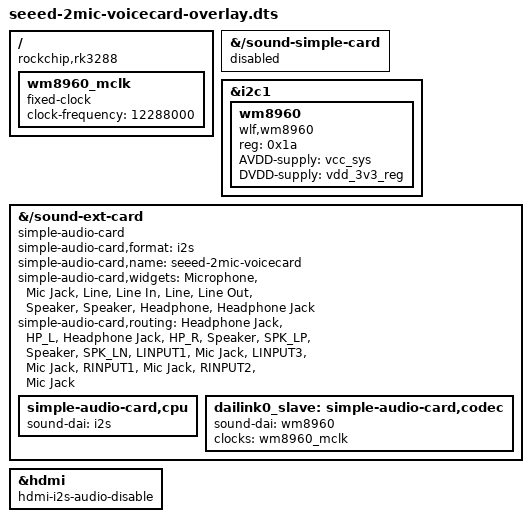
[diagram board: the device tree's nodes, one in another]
/dts-v1/;
/plugin/;

/ {
        compatible = "rockchip,rk3288";

        fragment@0 {
                target-path ="/sound-simple-card";
                __overlay__ {
                        status = "disabled";
                };
        };

        fragment@1 {
                target-path="/";
                __overlay__ {
                        wm8960_mclk: wm8960_mclk {
                                compatible = "fixed-clock";
                                #clock-cells = <0>;
                                clock-frequency = <12288000>;
                        };
                };
        };

        fragment@2 {
                target = <&i2c1>;
                __overlay__ {
                        #address-cells = <1>;
                        #size-cells = <0>;
                        status = "okay";

                        wm8960: wm8960 {
                                compatible = "wlf,wm8960";
                                reg = <0x1a>;
                                #sound-dai-cells = <0>;
                                AVDD-supply = <&vcc_sys>;
                                DVDD-supply = <&vdd_3v3_reg>;
                        };
                };
        };

        fragment@3 {
                target-path = "/sound-ext-card";
                slave_overlay: __overlay__ {
                        compatible = "simple-audio-card";
                        simple-audio-card,format = "i2s";
                        simple-audio-card,name = "seeed-2mic-voicecard";
                        status = "okay";
                        simple-audio-card,widgets =
                                "Microphone", "Mic Jack",
                                "Line", "Line In",
                                "Line", "Line Out",
                                "Speaker", "Speaker",
                                "Headphone", "Headphone Jack";
                        simple-audio-card,routing =
                                "Headphone Jack", "HP_L",
                                "Headphone Jack", "HP_R",
                                "Speaker", "SPK_LP",
                                "Speaker", "SPK_LN",
                                "LINPUT1", "Mic Jack",
                                "LINPUT3", "Mic Jack",
                                "RINPUT1", "Mic Jack",
                                "RINPUT2", "Mic Jack";

                        simple-audio-card,cpu {
                                sound-dai = <&i2s>;
                        };

                        dailink0_slave: simple-audio-card,codec {
                                sound-dai = <&wm8960>;
                                clocks = <&wm8960_mclk>;
                                clock-names = "mclk";
                        };
                };
        };

        fragment@4 {
                target = <&hdmi>;
                __overlay__ {
                        hdmi-i2s-audio-disable;
                };
        };

        __overrides__ {
                alsaname = <&slave_overlay>,"simple-audio-card,name";
                compatible = <&wm8960>,"compatible";
                master = <0>,"=2!3";
        };

};
